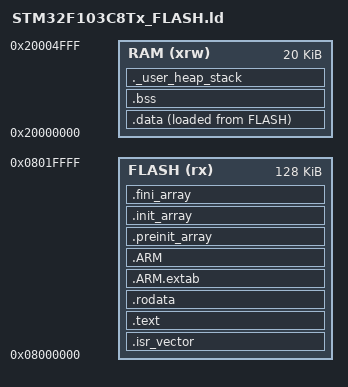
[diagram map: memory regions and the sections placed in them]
/* STM32F103C8 链接脚本（自写，最小化，结构同天空星）。Flash 长度由 Makefile 通过 -Wl,--defsym=__flash_kb=N 传入，
 * 取 board.yaml 的 mcu.flash_kb。SRAM 20KB。 */
ENTRY(Reset_Handler)

__flash_kb = DEFINED(__flash_kb) ? __flash_kb : 64;
_Min_Heap_Size  = 0x400;
_Min_Stack_Size = 0x800;

MEMORY
{
  FLASH (rx)  : ORIGIN = 0x08000000, LENGTH = 128K
  RAM   (xrw) : ORIGIN = 0x20000000, LENGTH = 20K
}
ASSERT(__flash_kb <= 128, "flash_kb 超出 F103x8/xB 最大 128KB")

_estack = ORIGIN(RAM) + LENGTH(RAM);

SECTIONS
{
  .isr_vector : { . = ALIGN(4); KEEP(*(.isr_vector)) . = ALIGN(4); } >FLASH

  .text :
  {
    . = ALIGN(4);
    *(.text) *(.text*) *(.glue_7) *(.glue_7t) *(.eh_frame)
    KEEP(*(.init)) KEEP(*(.fini))
    . = ALIGN(4);
    _etext = .;
  } >FLASH

  .rodata : { . = ALIGN(4); *(.rodata) *(.rodata*) . = ALIGN(4); } >FLASH

  .ARM.extab : { *(.ARM.extab* .gnu.linkonce.armextab.*) } >FLASH
  .ARM : { __exidx_start = .; *(.ARM.exidx*) __exidx_end = .; } >FLASH

  .preinit_array : { PROVIDE_HIDDEN(__preinit_array_start = .); KEEP(*(.preinit_array*)) PROVIDE_HIDDEN(__preinit_array_end = .); } >FLASH
  .init_array : { PROVIDE_HIDDEN(__init_array_start = .); KEEP(*(SORT(.init_array.*))) KEEP(*(.init_array*)) PROVIDE_HIDDEN(__init_array_end = .); } >FLASH
  .fini_array : { PROVIDE_HIDDEN(__fini_array_start = .); KEEP(*(SORT(.fini_array.*))) KEEP(*(.fini_array*)) PROVIDE_HIDDEN(__fini_array_end = .); } >FLASH

  _sidata = LOADADDR(.data);
  .data :
  {
    . = ALIGN(4);
    _sdata = .;
    *(.data) *(.data*)
    . = ALIGN(4);
    _edata = .;
  } >RAM AT> FLASH

  .bss :
  {
    . = ALIGN(4);
    _sbss = .; __bss_start__ = _sbss;
    *(.bss) *(.bss*) *(COMMON)
    . = ALIGN(4);
    _ebss = .; __bss_end__ = _ebss;
  } >RAM

  ._user_heap_stack :
  {
    . = ALIGN(8);
    PROVIDE(end = .); PROVIDE(_end = .);
    . = . + _Min_Heap_Size;
    . = . + _Min_Stack_Size;
    . = ALIGN(8);
  } >RAM

  ASSERT(_etext - ORIGIN(FLASH) + SIZEOF(.data) <= __flash_kb * 1024, "程序超出本板 Flash 容量（board.yaml mcu.flash_kb）")

  .ARM.attributes 0 : { *(.ARM.attributes) }
}
